# tle984x register map
Vendor: Infineon; File version: 1.9.5
CPU: CM0 r2p1, little endian, no MPU, no FPU, 2 interrupt priority bits
Registers are 32-bit, read-write, reset 0x0 unless marked. A register's access mark holds for its fields unless they carry their own. Offsets are from the block's base; [hi:lo] are bit positions; {n}, {i} and the like mark numbered series; 'fields as' and 'values as' point back to an identical list.

## PMU — Power Management Unit registers
Base 0x50004000
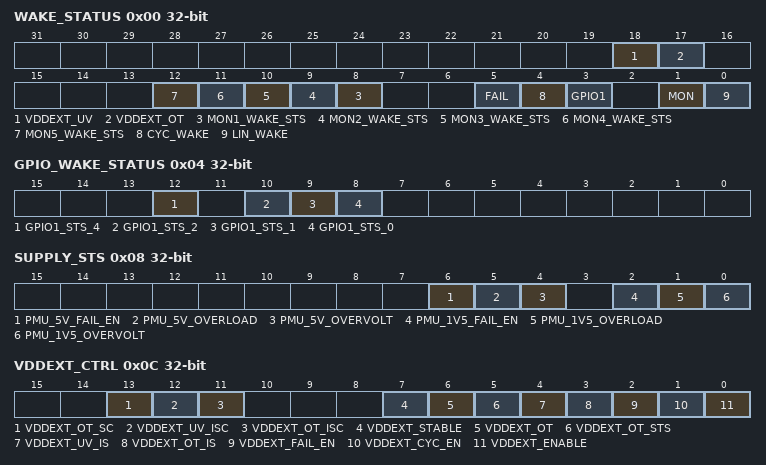
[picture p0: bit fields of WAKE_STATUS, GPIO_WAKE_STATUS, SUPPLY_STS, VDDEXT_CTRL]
0x00 WAKE_STATUS ro — Main wake status register
  [18] VDDEXT_UV — Wake VDDEXT undervoltage
    0=No wake-up detected; 1=Wake-up detected
  [17] VDDEXT_OT — Wake VDDEXT overtemperature
    0=No wake-up detected; 1=Wake-up detected
  [n+7] MON{n}_WAKE_STS (n=1..5) — Status of MON{n}
    0=No wake-up detected; 1=Wake-up detected
  [5] FAIL — Wake-up after VDDEXT fail
    0=No wake-up occurred; 1=Wake-up occurred
  [4] CYC_WAKE — Wake-up caused by cyclic wake
    0=No wake-up occurred; 1=Wake-up occurred
  [3] GPIO1 — Wake-up via GPIO1 which is a logical OR combination of all Wake_STS_GPIO1 bits
    0=No wake-up occurred; 1=Wake-up occurred
  [1] MON — Wake-up via MON which is a logical OR combination of all Wake_STS_MON bits
    0=No wake-up occurred; 1=Wake-up occurred
  [0] LIN_WAKE — Wake-up via LIN- Message
    0=No wake-up occurred; 1=Wake-up occurred
0x04 GPIO_WAKE_STATUS ro — GPIO port wake status register
  [all] fields
    0=No wake-up detected; 1=Wake-up detected
  [12] GPIO1_STS_4 — Wake GPIO1_4
  [10] GPIO1_STS_2 — Wake GPIO1_2
  [9] GPIO1_STS_1 — Wake GPIO1_1
  [8] GPIO1_STS_0 — Wake GPIO1_0
0x08 SUPPLY_STS — Voltage reg status register
  [6] PMU_5V_FAIL_EN — Enabling of VDDP status information as interrupt source
    0=No interrupts are generated; 1=Interrupts are generated
  [5] PMU_5V_OVERLOAD ro — Overload at VDDP regulator
    0=No_overload; 1=Overload
  [4] PMU_5V_OVERVOLT ro — Overvoltage at VDDP regulator
    0=No_overvoltage; 1=Overvoltage
  [2] PMU_1V5_FAIL_EN — Enabling of VDDC status information as interrupt source
    0=No interrupts are generated; 1=Interrupts are generated
  [1] PMU_1V5_OVERLOAD ro — Overload at VDDC regulator
    0=No_overload; 1=Overload
  [0] PMU_1V5_OVERVOLT ro — Overvoltage at VDDC regulator
    0=No_overvoltage; 1=Overvoltage
0x0C VDDEXT_CTRL — VDDEXT control register
  [13] VDDEXT_OT_SC wo — VDDEXT supply overtemperature status clear
    0=Status_not_cleared (VDDEXT overtemperature status not cleared); 1=Status_cleared (VDDEXT overtemperature status cleared)
  [12] VDDEXT_UV_ISC wo — VDDEXT supply undervoltage interrupt status clear
    0=Not_cleared (VDDEXT undervoltage not cleared); 1=Cleared (VDDEXT undervoltage cleared)
  [11] VDDEXT_OT_ISC wo — VDDEXT supply overtemperature interrupt status clear
    0=Not_cleared (VDDEXTovertemperature not cleared); 1=Cleared (VDDEXTovertemperature cleared)
  [7] VDDEXT_STABLE ro — VDDEXT supply stable
    0=Not_stable (VDDEXT not in stable condition); 1=Stable (VDDEXT in stable condition)
  [6] VDDEXT_OT ro — VDDEXT supply overtemperature
    0=No_overtemperature (VDDEXT not in overtemperature condition); 1=Overtemperature (VDDEXT in overtemperature condition)
  [5] VDDEXT_OT_STS ro — VDDEXT supply overtemperature status
    values as VDDEXT_OT
  [4] VDDEXT_UV_IS ro — VDDEXT supply undervoltage interrupt status
    0=Not_in_undervoltage (VDDEXT not in undervoltage condition); 1=In_undervoltage (VDDEXT in undervoltage condition)
  [3] VDDEXT_OT_IS ro — VDDEXT supply overtemperature interrupt status
    0=No_overtemperature (VDDEXT no overtemperature condition); 1=Overtemperature (VDDEXT overtemperature condition)
  [2] VDDEXT_FAIL_EN — Enabling of VDDEXT supply status information as interrupt source
    0=DISABLE (VDDEXT fail interrupts are disabled); 1=ENABLE (VDDEXT fail Interrupts are enabled)
  [1] VDDEXT_CYC_EN — VDDEXT supply for cyclic sense enable
    0=DISABLE (VDDEXT for cyclic sense disable); 1=ENABLE (VDDEXT for cyclic sense enable)
  [0] VDDEXT_ENABLE — VDDEXT supply enable
    0=DISABLE (VDDEXT supply disabled); 1=ENABLE (VDDEXT supply enabled)
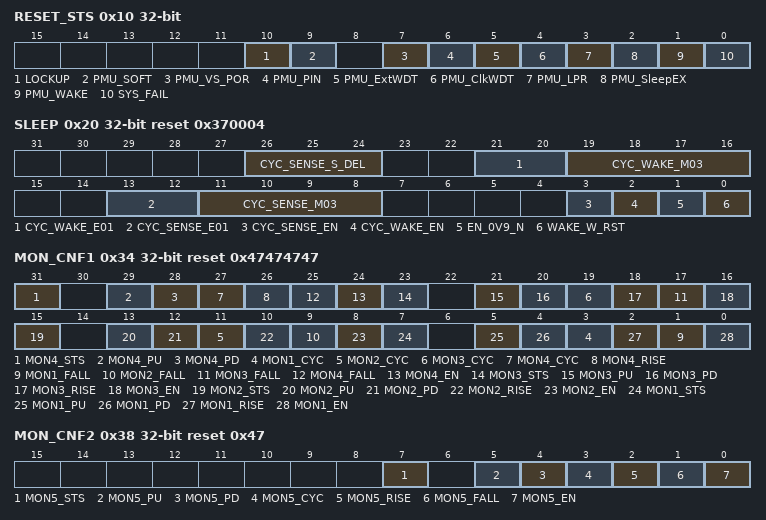
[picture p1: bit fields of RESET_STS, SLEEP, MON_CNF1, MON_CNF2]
0x10 RESET_STS — Reset status register
  [10] LOCKUP — Lockup-reset flag
    0=No_reset (No lockup-reset executed); 1=Reset (Lockup-reset executed)
  [9] PMU_SOFT — Soft-reset flag
    0=No_reset (No soft-reset executed); 1=Reset (Soft-reset executed)
  [7] PMU_VS_POR — Power-on reset flag
    0=No_reset (No power-on reset executed); 1=Reset (Power-on reset executed)
  [6] PMU_PIN — PIN-reset flag
    0=No_reset (No PIN-reset executed); 1=Reset (PIN-reset executed)
  [5] PMU_ExtWDT — External watchdog (WDT1) reset flag
    0=No_reset (No external watchdog reset executed); 1=Reset (External watchdog reset executed)
  [4] PMU_ClkWDT — Clock watchdog (CLKWDT) reset flag
    0=No_reset (Noclock watchdog reset executed); 1=Reset (Clock watchdog reset executed)
  [3] PMU_LPR — Low priority resets
    0=Low priority-reset executed; 1=Low priority executed
  [2] PMU_SleepEX — Flag which indicates a reset caused by sleep-exit
    0=No reset caused by sleep-exit executed; 1=Reset caused by sleep-exit executed
  [1] PMU_WAKE — Flag which indicates a reset caused by stop-exit
    0=No reset caused by stop-exit executed; 1=Reset caused by stop-exit executed
  [0] SYS_FAIL — Flag which indicates a reset caused by a system fail reported in the corresponding fail register
    0=No reset caused by system fail executed; 1=Reset caused by system fail executed
0x20 SLEEP reset 0x370004 — PMU sleep behavior register
  [26:24] CYC_SENSE_S_DEL — Sample delay in cyclic sense mode
    0=Delay_time_0 (Is 10 us); 1=Delay_time_1 (Is 20 us); 2=Delay_time_2 (Is 30 us); 3=Delay_time_3 (Is 40 us); 4=Delay_time_4 (Is 60 us); 5=Delay_time_5 (Is 80 us); 6=Delay_time_6 (Is 100 us); 7=Delay_time_7 (Is 150 us)
  [21:20] CYC_WAKE_E01 — Exponent
    {v}=Exponent_value_{v} (Exponent value is {v}) (v=0..3)
  [19:16] CYC_WAKE_M03 — Mantissa
    0=Mantissa_value_1 (Mantissa value is 1); 15=Mantissa_value_16 (Mantissa value is 16)
  [13:12] CYC_SENSE_E01 — Exponent
    {v}=Exponent_value_{v} (Exponent value is {v}) (v=0..3)
  [11:8] CYC_SENSE_M03 — Mantissa
    values as CYC_WAKE_M03
  [3] CYC_SENSE_EN — Enabling cyclic sense
    0=DISABLE (Cyclic sense disabled); 1=ENABLE (Cyclic sense enabled)
  [2] CYC_WAKE_EN — Enabling cyclic wake
    0=DISABLE (Cyclic wake disabled); 1=ENABLE (Cyclic wake enabled)
  [1] EN_0V9_N — Enables the reduction of the VDDC regulator output to reduced voltage during stop mode
    0=ENABLE (Output voltage reduction enabled); 1=DISABLE (Output voltage reduction disabled)
  [0] WAKE_W_RST — Wake-up with reset execution
    0=Without_reset_execution (Stop-exit without reset execution); 1=With_reset_execution (Stop-exit with reset execution)
0x34 MON_CNF1 reset 0x47474747 — Settings monitor 1-4 register
  [31] MON4_STS ro — MON4 status input
    0=Low_status (MON input has low status); 1=High_status (MON input has high status)
  [29] MON4_PU — Pull-up current source for MON4 input enable
    0=DISABLE (Pull-up source disabled); 1=ENABLE (Pull-up source enabled)
  [28] MON4_PD — Pull-down current source for MON4 input enable
    0=DISABLE (Pull-down source disabled); 1=ENABLE (Pull-down source enabled)
  [8n-5] MON{n}_CYC (n=1..4) — MON{n} for cycle sense enable
    0=DISABLE (Cycle sense disabled); 1=ENABLE (Cycle sense enabled)
  [26] MON4_RISE — MON4 wake-up on rising edge enable
    0=DISABLE (Wake-up disabled); 1=Enabled (Wake-up enabled)
  [8n-7] MON{n}_FALL (n=1..4) — MON{n} wake-up on falling edge enable
    0=DISABLE (Wake-up disabled); 1=ENABLE (Wake-up enabled)
  [24] MON4_EN — MON4 Enable
    0=DISABLE (MON4 disabled); 1=ENABLE (MON4 enabled)
  [23] MON3_STS ro — MON3 Status Input
    values as MON4_STS
  [21] MON3_PU — Pull-up current source for MON3 Input enable
    values as MON4_PU
  [20] MON3_PD — Pull-down current source for MON3 input enable
    values as MON4_PD
  [18] MON3_RISE — MON3 wake-up on rising edge enable
    0=DISABLE (Wake-up disabled); 1=ENABLE (Wake-up enabled)
  [16] MON3_EN — MON3 enable
    0=DISABLE (MON3 disabled); 1=ENABLE (MON3 enabled)
  [15] MON2_STS ro — MON2 status input
    values as MON4_STS
  [13] MON2_PU — Pull-up current source for MON2 input enable
    values as MON4_PU
  [12] MON2_PD — Pull-down current source for MON2 Input enable
    values as MON4_PD
  [10] MON2_RISE — MON2 wake-up on rising edge enable
    0=DISABLE (Wake-up disabled); 1=ENABLE (Wake-up enabled)
  [8] MON2_EN — MON2 enable
    0=DISABLE (MON2 disabled); 1=Enabled (MON2 enabled)
  [7] MON1_STS ro — MON1 status input
    values as MON4_STS
  [5] MON1_PU — Pull-up current source for MON1 input enable
    values as MON4_PU
  [4] MON1_PD — Pull-down current source for MON1 input enable
    values as MON4_PD
  [2] MON1_RISE — MON1 wake-up on rising edge enable
    0=DISABLE (Wake-up disabled); 1=ENABLE (Wake-up enabled)
  [0] MON1_EN — MON1 enable
    0=DISABLE (MON1 disabled); 1=ENABLE (MON1 enabled)
0x38 MON_CNF2 reset 0x47 — Settings monitor 5 register
  [7] MON5_STS ro — MON5 status input
    values as MON_CNF1.MON4_STS
  [5] MON5_PU — Pull-up current source for MON5 input enable
    values as MON_CNF1.MON4_PU
  [4] MON5_PD — Pull-down current source for MON5 input enable
    values as MON_CNF1.MON4_PD
  [3] MON5_CYC — MON5 for cycle sense enable
    values as MON_CNF1.MON1_CYC
  [2] MON5_RISE — MON5 wake-up on rising edge enable
    0=DISABLE (Wake-up disabled); 1=ENABLE (Wake-up enabled)
  [1] MON5_FALL — MON5 wake-up on falling edge enable
    0=DISABLE (Wake-up disabled); 1=ENABLE (Wake-up enabled)
  [0] MON5_EN — MON5 enable
    0=DISABLE (MON5 disabled); 1=ENABLE (MON5 enabled)
0x50 LIN_WAKE_EN — LIN wake enable register
  [7] LIN_EN — Lin wake enable
    0=DISABLE (Disabled); 1=ENABLE (Enabled)
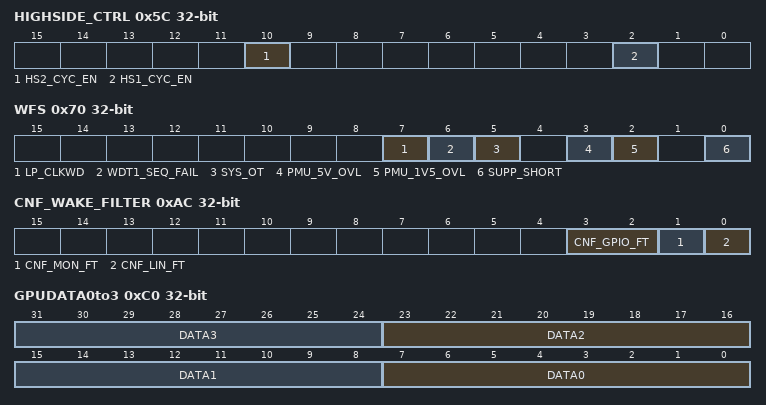
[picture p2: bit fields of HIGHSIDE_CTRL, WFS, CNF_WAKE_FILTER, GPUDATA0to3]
0x5C HIGHSIDE_CTRL — High-side control register
  [10] HS2_CYC_EN — High-side 2 switch enable for cyclic sense
    0=DISABLE (Disabled); 1=ENABLE (Enabled)
  [2] HS1_CYC_EN — High-side 1 switch enable for cyclic sense
    0=DISABLE (Disabled); 1=ENABLE (Enabled)
0x6C CNF_RST_TFB reset 0x3 — Reset blind time register
  [1:0] RST_TFB — Reset pin blind time selection bits
    0=0.5 us typ; 1=1 us typ; 2=5 us typ; 3=31 us typ
0x70 WFS ro — WFS system fail register
  [7] LP_CLKWD
    0=NORMAL (Normal operation); 1=FAIL (LP_CLK clock failure)
  [6] WDT1_SEQ_FAIL — External watchdog (WDT1) sequential fail
    0=No fail, system working properly; 1=Sequential_watchdog_fail (5 consecutive watchdog fails)
  [5] SYS_OT — System overtemperature indication flag
    0=NORMAL (Normal operation); 1=OT (Overtemperature)
  [3] PMU_5V_OVL — VDDP overload flag
    0=No_overload (VDDP ok); 1=Overload (VDDP overload)
  [2] PMU_1V5_OVL — VDDC overload flag
    0=No_overload (VDDC ok); 1=Overload (Hall VDDC overload)
  [0] SUPP_SHORT — Supply short
    0=Main_supply_ok (VDDP or VDDC are in expected range); 1=Main_supply_short (VDDP or VDDC do not have stable operating point)
0xAC CNF_WAKE_FILTER — PMU wake-up timing register
  [3:2] CNF_GPIO_FT — Wake-up filter time for general purpose IO
    0=10 us filter time; 1=20 us filter time; 2=40 us filter time; 3=5 us filter time
  [1] CNF_MON_FT — Wake-up filter time for monitoring inputs
    0=20 us filter time; 1=40 us filter time
  [0] CNF_LIN_FT — Wake-up filter time for LIN WAKE
    0=30 us filter time; 1=50 us filter time
0xC0 GPUDATA0to3 — General purpose user DATA0to3 register
  [8n+7:8n] DATA{n} (n=0..3) — DATA{n} storage byte
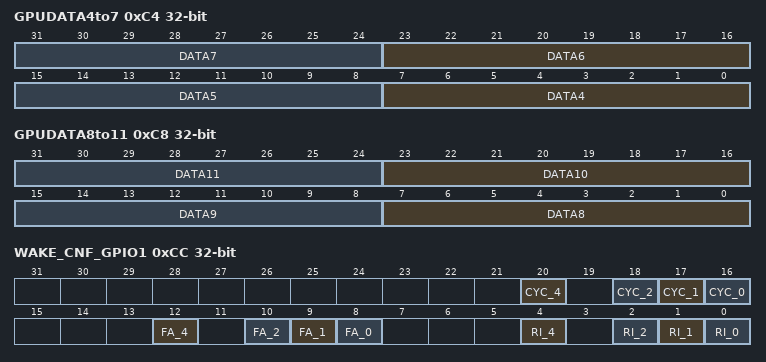
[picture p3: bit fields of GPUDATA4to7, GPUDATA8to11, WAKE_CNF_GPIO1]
0xC4 GPUDATA4to7 — General purpose user DATA4to7 register
  [8n-25:8n-32] DATA{n} (n=4..7) — DATA{n} storage byte
0xC8 GPUDATA8to11 — General purpose user DATA8to11 register
  [8n-57:8n-64] DATA{n} (n=8..11) — DATA{n} storage byte
0xCC WAKE_CNF_GPIO1 — Wake configuration GPIO port 1 register
  [20] CYC_4 — GPIO1_4 input for cycle sense enable
    0=DISABLE (Input for cycle sense disabled); 1=ENABLE (Input for cycle sense enabled)
  [18] CYC_2 — GPIO1_2 input for cycle sense enable
    values as CYC_4
  [17] CYC_1 — GPIO1_1 input for cycle sense enable
    values as CYC_4
  [16] CYC_0 — GPIO1_0 input for cycle sense enable
    values as CYC_4
  [12] FA_4 — Port 1_4 wake-up on falling edge enable
    0=DISABLE (Wake-up disabled); 1=ENABLE (Wake-up enabled)
  [10] FA_2 — Port 1_2 wake-up on falling edge enable
    0=DISABLE (Wake-up disabled); 1=ENABLE (Wake-up enabled)
  [9] FA_1 — Port 1_1 wake-up on falling edge enable
    0=DISABLE (Wake-up disabled); 1=ENABLE (Wake-up enabled)
  [8] FA_0 — Port 1_0 wake-up on falling edge enable
    0=DISABLE (Wake-up disabled); 1=ENABLE (Wake-up enabled)
  [4] RI_4 — Port 1_4 wake-up on rising edge enable
    0=DISABLE (Wake-up disabled); 1=ENABLE (Wake-up enabled)
  [2] RI_2 — Port 1_2 wake-up on rising edge enable
    0=DISABLE (Wake-up disabled); 1=ENABLE (Wake-up enabled)
  [1] RI_1 — Port 1_1 wake-up on rising edge enable
    0=DISABLE (Wake-up disabled); 1=ENABLE (Wake-up enabled)
  [0] RI_0 — Port 1_0 wake-up on rising edge enable
    0=DISABLE (Wake-up disabled); 1=ENABLE (Wake-up enabled)
